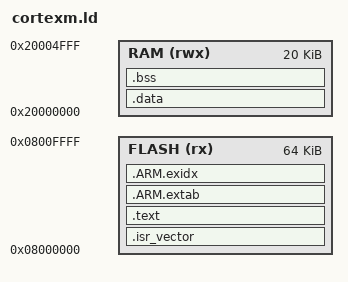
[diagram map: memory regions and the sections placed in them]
/* Minimal Cortex-M linker script for the raw .bin case study */
ENTRY(Reset_Handler)

MEMORY
{
  FLASH (rx)  : ORIGIN = 0x08000000, LENGTH = 64K
  RAM   (rwx) : ORIGIN = 0x20000000, LENGTH = 20K
}

/* Top of stack */
_estack = ORIGIN(RAM) + LENGTH(RAM);

SECTIONS
{
  /* Vector table at beginning of flash */
  .isr_vector ORIGIN(FLASH) :
  {
    KEEP(*(.isr_vector))
  } > FLASH

  /* Code and read-only data */
  .text :
  {
    *(.text*)
    *(.rodata*)
    *(.glue_7*)
    *(.glue_7t*)
  } > FLASH

  /* ARM unwind tables (may exist even with -fno-exceptions) */
  .ARM.extab :
  {
    *(.ARM.extab* .gnu.linkonce.armextab.*)
  } > FLASH

  .ARM.exidx :
  {
    __exidx_start = .;
    *(.ARM.exidx* .gnu.linkonce.armexidx.*)
    __exidx_end = .;
  } > FLASH

  /* LMA for initialized data in flash */
  _sidata = .;

  .data : AT(_sidata)
  {
    _sdata = .;
    *(.data*)
    _edata = .;
  } > RAM

  .bss (NOLOAD) :
  {
    _sbss = .;
    *(.bss*)
    *(COMMON)
    _ebss = .;
  } > RAM

  PROVIDE(__stack_top__ = _estack);
}
